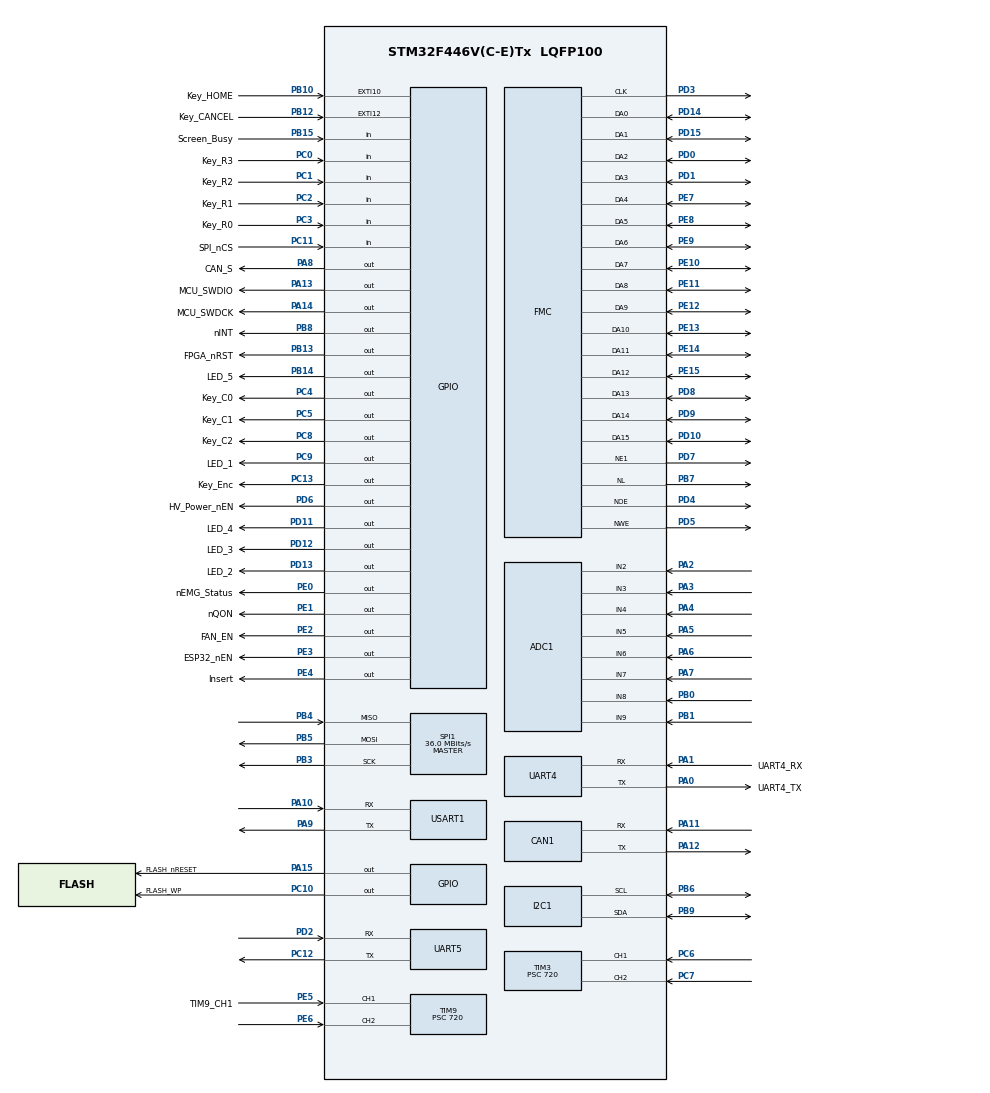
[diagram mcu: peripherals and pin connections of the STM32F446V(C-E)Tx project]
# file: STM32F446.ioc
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ADC1.Channel-10\#ChannelRegularConversion=ADC_CHANNEL_8
ADC1.Channel-11\#ChannelRegularConversion=ADC_CHANNEL_9
ADC1.Channel-4\#ChannelRegularConversion=ADC_CHANNEL_2
ADC1.Channel-5\#ChannelRegularConversion=ADC_CHANNEL_3
ADC1.Channel-6\#ChannelRegularConversion=ADC_CHANNEL_4
ADC1.Channel-7\#ChannelRegularConversion=ADC_CHANNEL_5
ADC1.Channel-8\#ChannelRegularConversion=ADC_CHANNEL_6
ADC1.Channel-9\#ChannelRegularConversion=ADC_CHANNEL_7
ADC1.ContinuousConvMode=DISABLE
ADC1.DiscontinuousConvMode=ENABLE
ADC1.InjNumberOfConversion=0
ADC1.NbrOfConversion=8
ADC1.NbrOfConversionFlag=1
ADC1.Rank-10\#ChannelRegularConversion=7
ADC1.Rank-11\#ChannelRegularConversion=8
ADC1.Rank-5\#ChannelRegularConversion=2
ADC1.Rank-6\#ChannelRegularConversion=3
ADC1.Rank-7\#ChannelRegularConversion=4
ADC1.Rank-8\#ChannelRegularConversion=5
ADC1.Rank-9\#ChannelRegularConversion=6
ADC1.SamplingTime-10\#ChannelRegularConversion=ADC_SAMPLETIME_15CYCLES
ADC1.SamplingTime-11\#ChannelRegularConversion=ADC_SAMPLETIME_15CYCLES
ADC1.SamplingTime-4\#ChannelRegularConversion=ADC_SAMPLETIME_15CYCLES
ADC1.SamplingTime-5\#ChannelRegularConversion=ADC_SAMPLETIME_15CYCLES
ADC1.SamplingTime-6\#ChannelRegularConversion=ADC_SAMPLETIME_15CYCLES
ADC1.SamplingTime-7\#ChannelRegularConversion=ADC_SAMPLETIME_15CYCLES
ADC1.SamplingTime-8\#ChannelRegularConversion=ADC_SAMPLETIME_15CYCLES
ADC1.SamplingTime-9\#ChannelRegularConversion=ADC_SAMPLETIME_15CYCLES
ADC1.ScanConvMode=ENABLE
ADC1.master=1
CAN1.CalculateTimeQuantum=444.44444444444446
Dma.MEMTOMEM.0.Direction=DMA_MEMORY_TO_MEMORY
Dma.MEMTOMEM.0.FIFOMode=DMA_FIFOMODE_ENABLE
Dma.MEMTOMEM.0.FIFOThreshold=DMA_FIFO_THRESHOLD_FULL
Dma.MEMTOMEM.0.Instance=DMA2_Stream0
Dma.MEMTOMEM.0.MemBurst=DMA_MBURST_INC8
Dma.MEMTOMEM.0.MemDataAlignment=DMA_MDATAALIGN_HALFWORD
Dma.MEMTOMEM.0.MemInc=DMA_MINC_ENABLE
Dma.MEMTOMEM.0.Mode=DMA_NORMAL
Dma.MEMTOMEM.0.PeriphBurst=DMA_PBURST_INC8
Dma.MEMTOMEM.0.PeriphDataAlignment=DMA_PDATAALIGN_HALFWORD
Dma.MEMTOMEM.0.PeriphInc=DMA_PINC_ENABLE
Dma.MEMTOMEM.0.Priority=DMA_PRIORITY_HIGH
Dma.Request0=MEMTOMEM
FMC.BusTurnAroundDuration1=0
FMC.CLKDivision1=2
FMC.WriteOperation1=FMC_WRITE_OPERATION_ENABLE
Mcu.Family=STM32F4
Mcu.Name=STM32F446V(C-E)Tx
Mcu.Package=LQFP100
NVIC.EXTI15_10_IRQn=true\:1\:0\:true\:false\:true\:true\:true
NVIC.I2C1_ER_IRQn=true\:0\:0\:false\:false\:true\:true\:true
NVIC.I2C1_EV_IRQn=true\:0\:0\:false\:false\:true\:true\:true
NVIC.PriorityGroup=NVIC_PRIORITYGROUP_4
NVIC.TIM1_BRK_TIM9_IRQn=true\:6\:0\:true\:false\:true\:true\:true
NVIC.TIM3_IRQn=true\:2\:0\:true\:false\:true\:true\:true
NVIC.TIM6_DAC_IRQn=true\:4\:0\:true\:false\:true\:true\:true
NVIC.TIM7_IRQn=true\:3\:0\:true\:false\:true\:true\:true
NVIC.UART4_IRQn=true\:1\:0\:true\:false\:true\:true\:true
NVIC.UART5_IRQn=true\:0\:0\:true\:false\:true\:true\:true
NVIC.USART1_IRQn=true\:5\:0\:true\:false\:true\:true\:true
PA0-WKUP.GPIO_Label=UART4_TX
PA0-WKUP.Mode=Asynchronous
PA0-WKUP.Signal=UART4_TX
PA1.GPIO_Label=UART4_RX
PA1.Mode=Asynchronous
PA1.Signal=UART4_RX
PA10.GPIO_ModeDefaultPP=GPIO_MODE_AF_PP
PA10.GPIO_PuPd=GPIO_NOPULL
PA10.GPIO_Speed=GPIO_SPEED_FREQ_VERY_HIGH
PA10.Mode=Asynchronous
PA10.Signal=USART1_RX
PA11.Mode=Master
PA11.Signal=CAN1_RX
PA12.Mode=Master
PA12.Signal=CAN1_TX
PA13.GPIO_Label=MCU_SWDIO
PA13.GPIO_ModeDefaultOutputPP=GPIO_MODE_OUTPUT_PP
PA13.GPIO_PuPd=GPIO_NOPULL
PA13.GPIO_Speed=GPIO_SPEED_FREQ_LOW
PA13.PinState=GPIO_PIN_RESET
PA13.Signal=GPIO_Output
PA14.GPIO_Label=MCU_SWDCK
PA14.GPIO_ModeDefaultOutputPP=GPIO_MODE_OUTPUT_PP
PA14.GPIO_PuPd=GPIO_NOPULL
PA14.GPIO_Speed=GPIO_SPEED_FREQ_LOW
PA14.PinState=GPIO_PIN_RESET
PA14.Signal=GPIO_Output
PA15.GPIO_Label=FLASH_nRESET
PA15.GPIO_ModeDefaultOutputPP=GPIO_MODE_OUTPUT_PP
PA15.GPIO_PuPd=GPIO_NOPULL
PA15.GPIO_Speed=GPIO_SPEED_FREQ_LOW
PA15.PinState=GPIO_PIN_RESET
PA15.Signal=GPIO_Output
PA2.Signal=ADCx_IN2
PA3.Signal=ADCx_IN3
PA4.Signal=ADCx_IN4
PA5.Signal=ADCx_IN5
PA6.Signal=ADCx_IN6
PA7.Signal=ADCx_IN7
PA8.GPIO_Label=CAN_S
PA8.GPIO_ModeDefaultOutputPP=GPIO_MODE_OUTPUT_PP
PA8.GPIO_PuPd=GPIO_NOPULL
PA8.GPIO_Speed=GPIO_SPEED_FREQ_LOW
PA8.PinState=GPIO_PIN_RESET
PA8.Signal=GPIO_Output
PA9.Mode=Asynchronous
PA9.Signal=USART1_TX
PB0.Signal=ADCx_IN8
PB1.Signal=ADCx_IN9
PB10.GPIO_Label=Key_HOME
PB10.Signal=GPXTI10
PB12.GPIO_Label=Key_CANCEL
PB12.Signal=GPXTI12
PB13.GPIO_Label=FPGA_nRST
PB13.GPIO_ModeDefaultOutputPP=GPIO_MODE_OUTPUT_PP
PB13.GPIO_PuPd=GPIO_NOPULL
PB13.GPIO_Speed=GPIO_SPEED_FREQ_LOW
PB13.PinState=GPIO_PIN_RESET
PB13.Signal=GPIO_Output
PB14.GPIO_Label=LED_5
PB14.Signal=GPIO_Output
PB15.GPIO_Label=Screen_Busy
PB15.Signal=GPIO_Input
PB3.Mode=Full_Duplex_Master
PB3.Signal=SPI1_SCK
PB4.Mode=Full_Duplex_Master
PB4.Signal=SPI1_MISO
PB5.Mode=Full_Duplex_Master
PB5.Signal=SPI1_MOSI
PB6.Mode=I2C
PB6.Signal=I2C1_SCL
PB7.Signal=FMC_NL
PB8.GPIO_Label=nINT
PB8.GPIO_ModeDefaultOutputPP=GPIO_MODE_OUTPUT_PP
PB8.GPIO_PuPd=GPIO_NOPULL
PB8.GPIO_Speed=GPIO_SPEED_FREQ_LOW
PB8.PinState=GPIO_PIN_RESET
PB8.Signal=GPIO_Output
PB9.Mode=I2C
PB9.Signal=I2C1_SDA
PC0.GPIO_Label=Key_R3
PC0.Signal=GPIO_Input
PC1.GPIO_Label=Key_R2
PC1.Signal=GPIO_Input
PC10.GPIO_Label=FLASH_WP
PC10.GPIO_ModeDefaultOutputPP=GPIO_MODE_OUTPUT_PP
PC10.GPIO_PuPd=GPIO_NOPULL
PC10.GPIO_Speed=GPIO_SPEED_FREQ_LOW
PC10.PinState=GPIO_PIN_RESET
PC10.Signal=GPIO_Output
PC11.GPIO_Label=SPI_nCS
PC11.Signal=GPIO_Input
PC12.Mode=Asynchronous
PC12.Signal=UART5_TX
PC13.GPIO_Label=Key_Enc
PC13.Signal=GPIO_Output
PC14-OSC32_IN.Mode=LSE-External-Oscillator
PC14-OSC32_IN.Signal=RCC_OSC32_IN
PC15-OSC32_OUT.Mode=LSE-External-Oscillator
PC15-OSC32_OUT.Signal=RCC_OSC32_OUT
PC2.GPIO_Label=Key_R1
PC2.Signal=GPIO_Input
PC3.GPIO_Label=Key_R0
PC3.Signal=GPIO_Input
PC4.GPIO_Label=Key_C0
PC4.GPIO_ModeDefaultOutputPP=GPIO_MODE_OUTPUT_OD
PC4.Signal=GPIO_Output
PC5.GPIO_Label=Key_C1
PC5.GPIO_ModeDefaultOutputPP=GPIO_MODE_OUTPUT_OD
PC5.Signal=GPIO_Output
PC6.Signal=S_TIM3_CH1
PC7.Signal=S_TIM3_CH2
PC8.GPIO_Label=Key_C2
PC8.Signal=GPIO_Output
PC9.GPIO_Label=LED_1
PC9.Signal=GPIO_Output
PD0.Mode=16b-da1
PD0.Signal=FMC_DA2
PD1.Mode=16b-da1
PD1.Signal=FMC_DA3
PD10.Mode=16b-da1
PD10.Signal=FMC_DA15
PD11.GPIO_Label=LED_4
PD11.Signal=GPIO_Output
PD12.GPIO_Label=LED_3
PD12.Signal=GPIO_Output
PD13.GPIO_Label=LED_2
PD13.Signal=GPIO_Output
PD14.Mode=16b-da1
PD14.Signal=FMC_DA0
PD15.Mode=16b-da1
PD15.Signal=FMC_DA1
PD2.Mode=Asynchronous
PD2.Signal=UART5_RX
PD3.Mode=BurstReadWrite1
PD3.Signal=FMC_CLK
PD4.Mode=MuxedPsram1
PD4.Signal=FMC_NOE
PD5.Mode=MuxedPsram1
PD5.Signal=FMC_NWE
PD6.GPIO_Label=HV_Power_nEN
PD6.GPIO_ModeDefaultOutputPP=GPIO_MODE_OUTPUT_PP
PD6.GPIO_PuPd=GPIO_PULLUP
PD6.GPIO_Speed=GPIO_SPEED_FREQ_LOW
PD6.PinState=GPIO_PIN_RESET
PD6.Signal=GPIO_Output
PD7.Mode=NorPsramChipSelect1_1
PD7.Signal=FMC_NE1
PD8.Mode=16b-da1
PD8.Signal=FMC_DA13
PD9.Mode=16b-da1
PD9.Signal=FMC_DA14
PE0.GPIO_Label=nEMG_Status
PE0.GPIO_ModeDefaultOutputPP=GPIO_MODE_OUTPUT_PP
PE0.GPIO_PuPd=GPIO_NOPULL
PE0.GPIO_Speed=GPIO_SPEED_FREQ_LOW
PE0.PinState=GPIO_PIN_RESET
PE0.Signal=GPIO_Output
PE1.GPIO_Label=nQON
PE1.GPIO_ModeDefaultOutputPP=GPIO_MODE_OUTPUT_PP
PE1.GPIO_PuPd=GPIO_NOPULL
PE1.GPIO_Speed=GPIO_SPEED_FREQ_LOW
PE1.PinState=GPIO_PIN_RESET
PE1.Signal=GPIO_Output
PE10.Mode=16b-da1
PE10.Signal=FMC_DA7
PE11.Mode=16b-da1
PE11.Signal=FMC_DA8
PE12.Mode=16b-da1
PE12.Signal=FMC_DA9
PE13.Mode=16b-da1
PE13.Signal=FMC_DA10
PE14.Mode=16b-da1
PE14.Signal=FMC_DA11
PE15.Mode=16b-da1
PE15.Signal=FMC_DA12
PE2.GPIO_Label=FAN_EN
PE2.GPIO_ModeDefaultOutputPP=GPIO_MODE_OUTPUT_PP
PE2.GPIO_PuPd=GPIO_PULLUP
PE2.GPIO_Speed=GPIO_SPEED_FREQ_LOW
PE2.PinState=GPIO_PIN_RESET
PE2.Signal=GPIO_Output
PE3.GPIO_Label=ESP32_nEN
PE3.GPIO_ModeDefaultOutputPP=GPIO_MODE_OUTPUT_PP
PE3.GPIO_PuPd=GPIO_NOPULL
PE3.GPIO_Speed=GPIO_SPEED_FREQ_LOW
PE3.PinState=GPIO_PIN_RESET
PE3.Signal=GPIO_Output
PE4.GPIO_Label=Insert
PE4.Signal=GPIO_Output
PE5.GPIO_Label=TIM9_CH1
PE5.Signal=S_TIM9_CH1
PE6.Signal=S_TIM9_CH2
PE7.Mode=16b-da1
PE7.Signal=FMC_DA4
PE8.Mode=16b-da1
PE8.Signal=FMC_DA5
PE9.Mode=16b-da1
PE9.Signal=FMC_DA6
PH0-OSC_IN.Mode=HSE-External-Oscillator
PH0-OSC_IN.Signal=RCC_OSC_IN
PH1-OSC_OUT.Mode=HSE-External-Oscillator
PH1-OSC_OUT.Signal=RCC_OSC_OUT
ProjectManager.HeapSize=0x200
ProjectManager.StackSize=0x400
ProjectManager.TargetToolchain=MDK-ARM V5
RCC.AHBFreq_Value=72000000
RCC.APB1CLKDivider=RCC_HCLK_DIV2
RCC.APB1Freq_Value=36000000
RCC.APB1TimFreq_Value=72000000
RCC.APB2Freq_Value=72000000
RCC.APB2TimFreq_Value=72000000
RCC.CortexFreq_Value=72000000
RCC.HCLKFreq_Value=72000000
RCC.HSE_VALUE=16000000
RCC.PLLN=144
RCC.PLLSourceVirtual=RCC_PLLSOURCE_HSE
RCC.SYSCLKFreq_VALUE=72000000
RCC.SYSCLKSource=RCC_SYSCLKSOURCE_PLLCLK
RCC.USBFreq_Value=72000000
RCC.VCOOutputFreq_Value=144000000
SH.ADCx_IN2.0=ADC1_IN2,IN2
SH.ADCx_IN3.0=ADC1_IN3,IN3
SH.ADCx_IN4.0=ADC1_IN4,IN4
SH.ADCx_IN5.0=ADC1_IN5,IN5
SH.ADCx_IN6.0=ADC1_IN6,IN6
SH.ADCx_IN7.0=ADC1_IN7,IN7
SH.ADCx_IN8.0=ADC1_IN8,IN8
SH.ADCx_IN9.0=ADC1_IN9,IN9
SH.FMC_NL.0=FMC_NL,AddressValid1
SH.S_TIM3_CH1.0=TIM3_CH1,Input_Capture1_from_TI1
SH.S_TIM3_CH2.0=TIM3_CH2,Input_Capture2_from_TI2
SH.S_TIM9_CH1.0=TIM9_CH1,Input_Capture1_from_TI1
SH.S_TIM9_CH2.0=TIM9_CH2,Input_Capture2_from_TI2
SPI1.CalculateBaudRate=36.0 MBits/s
SPI1.Direction=SPI_DIRECTION_2LINES
SPI1.Mode=SPI_MODE_MASTER
SPI1.VirtualType=VM_MASTER
TIM3.Channel-Input_Capture1_from_TI1=TIM_CHANNEL_1
TIM3.Channel-Input_Capture2_from_TI2=TIM_CHANNEL_2
TIM3.ICPolarity_CH1=TIM_INPUTCHANNELPOLARITY_RISING
TIM3.ICPolarity_CH2=TIM_INPUTCHANNELPOLARITY_RISING
TIM3.ICPrescaler-Input_Capture1_from_TI1=TIM_ICPSC_DIV1
TIM3.Period=1000
TIM3.Prescaler=720
TIM6.Period=7199
TIM6.Prescaler=4999
TIM7.Period=1000
TIM7.Prescaler=720
TIM9.Channel-Input_Capture1_from_TI1=TIM_CHANNEL_1
TIM9.Channel-Input_Capture2_from_TI2=TIM_CHANNEL_2
TIM9.Period=1000
TIM9.Prescaler=720
UART4.VirtualMode=Asynchronous
UART5.VirtualMode=Asynchronous
USART1.VirtualMode=VM_ASYNC
VP_TIM6_VS_ClockSourceINT.Mode=Enable_Timer
VP_TIM7_VS_ClockSourceINT.Mode=Enable_Timer
board=custom

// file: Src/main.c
/* USER CODE BEGIN Header */
/**
  ******************************************************************************
  * @file           : main.c
  * @brief          : Main program body
  ******************************************************************************
  * @attention
  *
  * <h2><center>&copy; Copyright (c) 2021 STMicroelectronics.
  * All rights reserved.</center></h2>
  *
  * This software component is licensed by ST under BSD 3-Clause license,
  * the "License"; You may not use this file except in compliance with the
  * License. You may obtain a copy of the License at:
  *                        opensource.org/licenses/BSD-3-Clause
  *
  ******************************************************************************
  */
/* USER CODE END Header */
#include "main.h"
#include "adc.h"
#include "can.h"
#include "dma.h"
#include "i2c.h"
#include "spi.h"
#include "tim.h"
#include "usart.h"
#include "gpio.h"
#include "fmc.h"

/* USER CODE BEGIN Includes */
#include "sys.h"
#include "delay.h"
#include "UART_menu.h"
#include "esp32.h"
#include "Screen.h"
/* USER CODE END Includes */

void SystemClock_Config(void);

int main(void)
{
  /* USER CODE BEGIN 1 */

	uint8_t Led_flag = 0;
  /* USER CODE END 1 */

  /* MCU Configuration--------------------------------------------------------*/

  /* Reset of all peripherals, Initializes the Flash interface and the Systick. */
  HAL_Init();

  /* Configure the system clock */
  SystemClock_Config();

  /* Initialize all configured peripherals */
  MX_GPIO_Init();
  MX_DMA_Init();
  MX_FMC_Init();
  MX_USART1_UART_Init();
  MX_TIM7_Init();
  MX_CAN1_Init();
  MX_UART5_Init();
  MX_ADC1_Init();
  MX_I2C1_Init();
  MX_TIM3_Init();
  MX_TIM9_Init();
  MX_SPI1_Init();
  MX_UART4_Init();
  MX_TIM6_Init();
  /* USER CODE BEGIN 2 */
  delay_init(72);               	//初始化延时函数
	LL_USART_EnableIT_RXNE(USART1);
	LL_USART_EnableIT_PE(USART1);
	//LL_USART_EnableIT_RXNE(UART4);
	//LL_USART_EnableIT_PE(UART4);
	LL_USART_EnableIT_RXNE(UART5);
	LL_USART_EnableIT_PE(UART5);

	SCL_OUT();    //IIC初始电平设置
	SDA_OUT();
	LL_GPIO_SetOutputPin(GPIOB,LL_GPIO_PIN_6);
	LL_GPIO_SetOutputPin(GPIOB,LL_GPIO_PIN_9);
	BQ_25792_init();   //电池管理初始化

	LL_GPIO_SetOutputPin(ESP32_nEN_GPIO_Port,ESP32_nEN_Pin);       //ESP32复位
	LL_GPIO_SetOutputPin(FPGA_nRST_GPIO_Port,FPGA_nRST_Pin);       //FPGA复位
	LL_GPIO_SetOutputPin(HV_Power_nEN_GPIO_Port,HV_Power_nEN_Pin); //Power复位
	LL_GPIO_ResetOutputPin(GPIOE,FAN_EN_Pin);                      //风扇复位
	LL_GPIO_SetOutputPin(GPIOE,FAN_EN_Pin);                        //风扇启动

	LL_GPIO_SetOutputPin(GPIOC,LED_1_Pin); //错误，故障，电量低指示灯   //此时LED1和LED2配合，点亮LED2 绿灯，标志电源输入
	LL_GPIO_ResetOutputPin(GPIOD,LED_2_Pin); //交流电输入指示
	LL_GPIO_SetOutputPin(GPIOD,LED_3_Pin);

	LL_GPIO_SetOutputPin(GPIOD,LED_4_Pin); //就绪（闪）运行（常亮）此时处于淡蓝色状态，标志FES处于初始化状态
	LL_GPIO_SetOutputPin(GPIOD,LED_5_Pin);

	LL_GPIO_SetOutputPin(GPIOC,Key_C0_Pin); //键盘扫描初始化
	LL_GPIO_SetOutputPin(GPIOC,Key_C1_Pin);
	LL_GPIO_SetOutputPin(GPIOC,Key_C2_Pin);

	TIM3_init();       //飞梭TIM3初始化
	delay_ms(4000);
	Screen_init();     //刺激器参数初始化

	uint8_t FES_out = 0;
	uint8_t FES_Cnt = 6;  //周期计数 总需求 *6
	uint8_t FES_Flag = 0; //默认开始静息状态
	uint8_t Relax_Flag = 1;
	extern  uint16_t sec_cnt;

  /* USER CODE END 2 */

  /* Infinite loop */
  /* USER CODE BEGIN WHILE */
  while (1)
  {
		//UART_menu();

//		if(sec_cnt==0){
//			if(Relax_Flag){  //静息结束，开始电刺激
//				FES_Flag = 1;
//				Relax_Flag = 0;
//				sec_cnt = 480;
//				FES_Cnt--;
//				printf("FES_Cnt = %d",FES_Cnt);
//			}
//			else{ //电刺激结束 开始静息
//				FES_Flag = 0;
//				Relax_Flag = 1;
//				sec_cnt = 120;
//			}
//		}
		if(Start_flag){
			ADC_Value();
	    LL_GPIO_ResetOutputPin(GPIOC,LED_1_Pin); //错误，故障，电量低指示灯  LED1 LED2同时点亮，黄灯，标志FES开始输出
	    LL_GPIO_ResetOutputPin(GPIOD,LED_2_Pin); //交流电输入指示
			LL_GPIO_SetOutputPin(GPIOD,LED_4_Pin); //就绪（闪）运行（常亮） 点亮LED5 蓝色灯 标志FES开始输出
			Led_flag = 0;
			}
		else {
			if(Led_flag==50){
				Led_flag = 0;
			  LED_4 = ~LED_4; //闪烁态 标志FES准备就绪
		    LL_GPIO_SetOutputPin(GPIOC,LED_1_Pin); //错误，故障，电量低指示灯  仅点亮LED2 绿灯 标志FES处于准备状态
      	LL_GPIO_ResetOutputPin(GPIOD,LED_2_Pin); //交流电输入指示
			}
			else Led_flag++;
		}

		Screen_fmc_fpga();	 //屏幕扫描
		Screen_current_value();  //输出扫描
		if(FPGA_RESET>500) {
			printf("FPGA_RESET = %d \r\n",FPGA_RESET);
			Screen_RESET_init();
			FPGA_RESET = 0;
		}

//    Key_Scan();  //键盘扫描

    /* USER CODE END WHILE */

  }
}

void SystemClock_Config(void)
{
  LL_FLASH_SetLatency(LL_FLASH_LATENCY_2);
  while(LL_FLASH_GetLatency()!= LL_FLASH_LATENCY_2)
  {
  }
  LL_PWR_SetRegulVoltageScaling(LL_PWR_REGU_VOLTAGE_SCALE3);
  LL_PWR_DisableOverDriveMode();
  LL_RCC_HSE_Enable();

   /* Wait till HSE is ready */
  while(LL_RCC_HSE_IsReady() != 1)
  {

  }
  LL_RCC_PLL_ConfigDomain_SYS(LL_RCC_PLLSOURCE_HSE, LL_RCC_PLLM_DIV_16, 144, LL_RCC_PLLP_DIV_2);
  LL_RCC_PLL_Enable();

   /* Wait till PLL is ready */
  while(LL_RCC_PLL_IsReady() != 1)
  {

  }
  LL_RCC_SetAHBPrescaler(LL_RCC_SYSCLK_DIV_1);
  LL_RCC_SetAPB1Prescaler(LL_RCC_APB1_DIV_2);
  LL_RCC_SetAPB2Prescaler(LL_RCC_APB2_DIV_1);
  LL_RCC_SetSysClkSource(LL_RCC_SYS_CLKSOURCE_PLL);

   /* Wait till System clock is ready */
  while(LL_RCC_GetSysClkSource() != LL_RCC_SYS_CLKSOURCE_STATUS_PLL)
  {

  }
  LL_SetSystemCoreClock(72000000);

   /* Update the time base */
  if (HAL_InitTick (TICK_INT_PRIORITY) != HAL_OK)
  {
    Error_Handler();
  }
  LL_RCC_SetTIMPrescaler(LL_RCC_TIM_PRESCALER_TWICE);
}

void Error_Handler(void)
{
}

/************************ (C) COPYRIGHT STMicroelectronics *****END OF FILE****/
